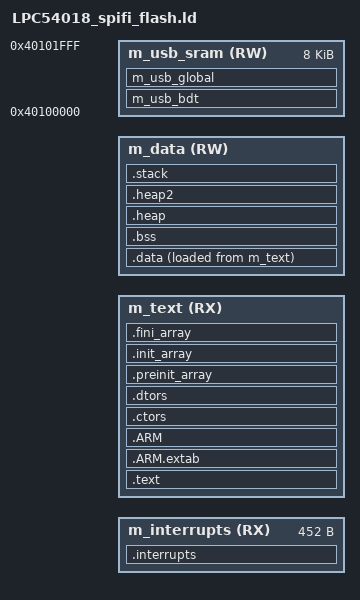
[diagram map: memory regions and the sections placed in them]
/*
** ###################################################################
**     Processors:          LPC54018JBD208
**                          LPC54018JET180
**
**     Compiler:            GNU C Compiler
**     Reference manual:    LPC540xx User manual Rev.0.2 19 October 2017
**     Version:             rev. 1.2, 2017-06-08
**     Build:               b170823
**
**     Abstract:
**         Linker file for the GNU C Compiler
**
**     The Clear BSD License
**     Copyright 2016 Freescale Semiconductor, Inc.
**     Copyright 2016-2017 NXP
**     All rights reserved.
**     
**     Redistribution and use in source and binary forms, with or without modification,
**     are permitted (subject to the limitations in the disclaimer below) provided
**      that the following conditions are met:
**
**     1. Redistributions of source code must retain the above copyright notice, this list
**       of conditions and the following disclaimer.
**
**     2. Redistributions in binary form must reproduce the above copyright notice, this
**       list of conditions and the following disclaimer in the documentation and/or
**       other materials provided with the distribution.
**
**     3. Neither the name of the copyright holder nor the names of its
**       contributors may be used to endorse or promote products derived from this
**       software without specific prior written permission.
**
**     NO EXPRESS OR IMPLIED LICENSES TO ANY PARTY'S PATENT RIGHTS ARE GRANTED BY THIS LICENSE.
**     THIS SOFTWARE IS PROVIDED BY THE COPYRIGHT HOLDERS AND CONTRIBUTORS "AS IS" AND
**     ANY EXPRESS OR IMPLIED WARRANTIES, INCLUDING, BUT NOT LIMITED TO, THE IMPLIED
**     WARRANTIES OF MERCHANTABILITY AND FITNESS FOR A PARTICULAR PURPOSE ARE
**     DISCLAIMED. IN NO EVENT SHALL THE COPYRIGHT HOLDER OR CONTRIBUTORS BE LIABLE FOR
**     ANY DIRECT, INDIRECT, INCIDENTAL, SPECIAL, EXEMPLARY, OR CONSEQUENTIAL DAMAGES
**     (INCLUDING, BUT NOT LIMITED TO, PROCUREMENT OF SUBSTITUTE GOODS OR SERVICES;
**     LOSS OF USE, DATA, OR PROFITS; OR BUSINESS INTERRUPTION) HOWEVER CAUSED AND ON
**     ANY THEORY OF LIABILITY, WHETHER IN CONTRACT, STRICT LIABILITY, OR TORT
**     (INCLUDING NEGLIGENCE OR OTHERWISE) ARISING IN ANY WAY OUT OF THE USE OF THIS
**     SOFTWARE, EVEN IF ADVISED OF THE POSSIBILITY OF SUCH DAMAGE.
**
**     http:                 www.nxp.com
**     mail:                 support@nxp.com
**
** ###################################################################
*/



/* Entry Point */
ENTRY(Reset_Handler)

HEAP_SIZE  = DEFINED(__heap_size__)  ? __heap_size__  : 0x8000;
STACK_SIZE = DEFINED(__stack_size__) ? __stack_size__ : 0x0800;

IMAGE_START_ADDR  = DEFINED(XIP_IMAGE)  ? 0x10000000  : 0x00000000;
DATA_START_ADDR   = DEFINED(XIP_IMAGE)  ? 0x00000004  : 0x20000000;
TEXT_SECTION_SIZE = DEFINED(XIP_IMAGE)  ? 0x00FFFE3C  : 0x0002FE3C;
DATA_SECTION_SIZE = DEFINED(XIP_IMAGE)  ? 0x0002FFFC  : 0x00028000;

/* Specify the memory areas */
MEMORY
{
  m_interrupts          (RX)  : ORIGIN = IMAGE_START_ADDR, LENGTH = 0x000001C4
  m_text                (RX)  : ORIGIN = IMAGE_START_ADDR + LENGTH(m_interrupts), LENGTH = TEXT_SECTION_SIZE
  m_data                (RW)  : ORIGIN = DATA_START_ADDR, LENGTH = DATA_SECTION_SIZE
  m_usb_sram            (RW)  : ORIGIN = 0x40100000, LENGTH = 0x00002000
}

/* Define output sections */
SECTIONS
{
  /* The startup code goes first into internal flash */
  .interrupts :
  {
    __vector_start = .;
    . = ALIGN(4);
    KEEP(*(.isr_vector))     /* Startup code */
    . = ALIGN(4);
  } > m_interrupts

  /* The program code and other data goes into internal flash */
  .text :
  {
    . = ALIGN(4);
    *(.text)                 /* .text sections (code) */
    *(.text*)                /* .text* sections (code) */
    *(.rodata)               /* .rodata sections (constants, strings, etc.) */
    *(.rodata*)              /* .rodata* sections (constants, strings, etc.) */
    *(.glue_7)               /* glue arm to thumb code */
    *(.glue_7t)              /* glue thumb to arm code */
    *(.eh_frame)
    KEEP (*(.init))
    KEEP (*(.fini))
    . = ALIGN(4);
  } > m_text

  .ARM.extab :
  {
    *(.ARM.extab* .gnu.linkonce.armextab.*)
  } > m_text

  .ARM :
  {
    __exidx_start = .;
    *(.ARM.exidx*)
    __exidx_end = .;
  } > m_text

 .ctors :
  {
    __CTOR_LIST__ = .;
    /* gcc uses crtbegin.o to find the start of
       the constructors, so we make sure it is
       first.  Because this is a wildcard, it
       doesn't matter if the user does not
       actually link against crtbegin.o; the
       linker won't look for a file to match a
       wildcard.  The wildcard also means that it
       doesn't matter which directory crtbegin.o
       is in.  */
    KEEP (*crtbegin.o(.ctors))
    KEEP (*crtbegin?.o(.ctors))
    /* We don't want to include the .ctor section from
       from the crtend.o file until after the sorted ctors.
       The .ctor section from the crtend file contains the
       end of ctors marker and it must be last */
    KEEP (*(EXCLUDE_FILE(*crtend?.o *crtend.o) .ctors))
    KEEP (*(SORT(.ctors.*)))
    KEEP (*(.ctors))
    __CTOR_END__ = .;
  } > m_text

  .dtors :
  {
    __DTOR_LIST__ = .;
    KEEP (*crtbegin.o(.dtors))
    KEEP (*crtbegin?.o(.dtors))
    KEEP (*(EXCLUDE_FILE(*crtend?.o *crtend.o) .dtors))
    KEEP (*(SORT(.dtors.*)))
    KEEP (*(.dtors))
    __DTOR_END__ = .;
  } > m_text

  .preinit_array :
  {
    PROVIDE_HIDDEN (__preinit_array_start = .);
    KEEP (*(.preinit_array*))
    PROVIDE_HIDDEN (__preinit_array_end = .);
  } > m_text

  .init_array :
  {
    PROVIDE_HIDDEN (__init_array_start = .);
    KEEP (*(SORT(.init_array.*)))
    KEEP (*(.init_array*))
    PROVIDE_HIDDEN (__init_array_end = .);
  } > m_text

  .fini_array :
  {
    PROVIDE_HIDDEN (__fini_array_start = .);
    KEEP (*(SORT(.fini_array.*)))
    KEEP (*(.fini_array*))
    PROVIDE_HIDDEN (__fini_array_end = .);
  } > m_text

  __etext = .;    /* define a global symbol at end of code */
  __DATA_ROM = .; /* Symbol is used by startup for data initialization */

  .data : ALIGN(4)
  {
    . = ALIGN(4);
    __DATA_RAM = .;
    __data_start__ = .;      /* create a global symbol at data start */
    *(.ramfunc*)             /* for functions in ram */
    *(.data)                 /* .data sections */
    *(.data*)                /* .data* sections */
    KEEP(*(.jcr*))
    . = ALIGN(4);
    __data_end__ = .;        /* define a global symbol at data end */
  } > m_data AT>m_text
  
  __DATA_END = __DATA_ROM + (__data_end__ - __data_start__);
  __IMAGE_START = LOADADDR(.interrupts);
  __IMAGE_END = LOADADDR(.data) + SIZEOF(.data);
  __IMAGE_SIZE = __IMAGE_END - __IMAGE_START;

  text_end = ORIGIN(m_text) + LENGTH(m_text);
  ASSERT(__DATA_END <= text_end, "region m_text overflowed with text and data")

  /* Uninitialized data section */
  .bss :
  {
    /* This is used by the startup in order to initialize the .bss section */
    . = ALIGN(4);
    __START_BSS = .;
    __bss_start__ = .;
    *(.bss)
    *(.bss*)
    *(COMMON)
    . = ALIGN(4);
    __bss_end__ = .;
    __END_BSS = .;
  } > m_data

  .heap :
  {
    . = ALIGN(8);
    __end__ = .;
    PROVIDE(end = .);
    __HeapBase = .;
    . += HEAP_SIZE;
    __HeapLimit = .;
    __heap_limit = .; /* Add for _sbrk */
  } > m_data

  .heap2 :
  {
    . = ALIGN(8);
    __end__ = .;
    PROVIDE(end = .);
    __Heap2Base = .;
    . += HEAP_SIZE;
    __Heap2Limit = .;
    __heap_limit2 = .; /* Add for _sbrk */
  } > m_data

  .stack :
  {
    . = ALIGN(8);
    . += STACK_SIZE;
  } > m_data

  m_usb_bdt (NOLOAD) :
  {
    . = ALIGN(512);
    *(m_usb_bdt)
  } > m_usb_sram

  m_usb_global (NOLOAD) :
  {
    *(m_usb_global)
  } > m_usb_sram

  /* Initializes stack on the end of block */
  __StackTop   = ORIGIN(m_data) + LENGTH(m_data);
  __StackLimit = __StackTop - STACK_SIZE;
  PROVIDE(__stack = __StackTop);

  .ARM.attributes 0 : { *(.ARM.attributes) }

  ASSERT(__StackLimit >= __HeapLimit, "region m_data overflowed with stack and heap")
}

